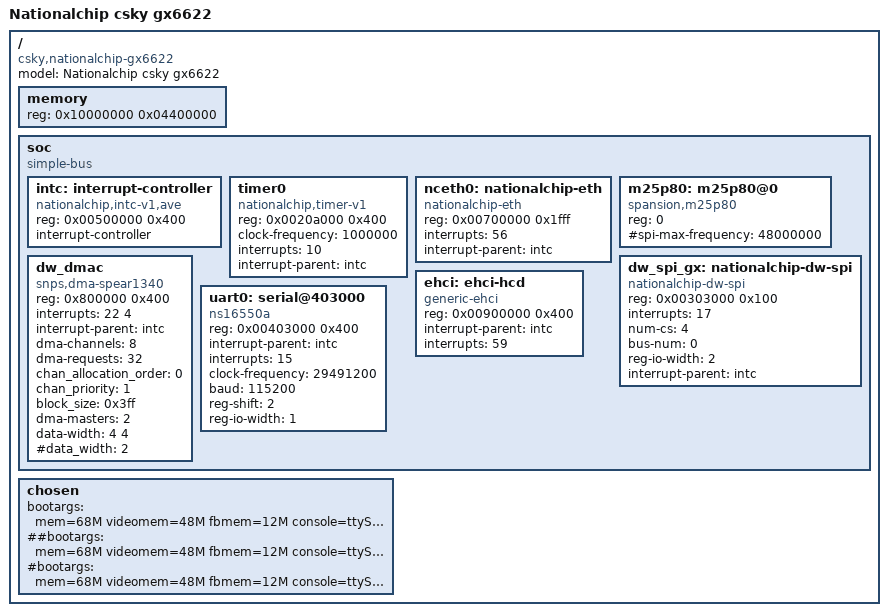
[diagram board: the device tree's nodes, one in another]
/dts-v1/;
/ {
	model = "Nationalchip csky gx6622";
	compatible = "csky,nationalchip-gx6622";
	#address-cells = <1>;
	#size-cells = <1>;

	memory {
		device_type = "memory";
		reg = <0x10000000 0x04400000>;
	};

	soc {
		#address-cells = <1>;
		#size-cells = <1>;
		compatible = "simple-bus";
		ranges;

		intc: interrupt-controller {
			compatible = "nationalchip,intc-v1,ave";
			reg = <0x00500000 0x400>;
			interrupt-controller;
			#interrupt-cells = <1>;
		};

		timer0 {
			compatible = "nationalchip,timer-v1";
			reg = <0x0020a000 0x400>;
			clock-frequency = <1000000>;
			interrupts = <10>;
			interrupt-parent = <&intc>;
		};

		nceth0: nationalchip-eth {
			compatible = "nationalchip-eth";
			reg = <0x00700000 0x1fff>;
			interrupts = <56>;
			interrupt-parent = <&intc>;
		};

		m25p80: m25p80@0 {
			compatible = "spansion,m25p80", "jedec,spi-nor";
			reg = <0>;				/* CS0 */
			#spi-max-frequency = <48000000>;
		};

		dw_spi_gx: nationalchip-dw-spi {
			compatible = "nationalchip-dw-spi";
			reg = <0x00303000 0x100>;
			interrupts = <17>;
			num-cs = <4>;
			bus-num = <0>;
			reg-io-width = <2>;
			interrupt-parent = <&intc>;
		};

		dw_dmac: dw_dmac {
			compatible = "snps,dma-spear1340";
			reg = <0x800000 0x400>;
			interrupts = <22 4>;
			interrupt-parent = <&intc>;
            
			dma-channels = <8>;
			#dma-cells = <3>;
			dma-requests = <32>;
			chan_allocation_order = <0>;
			chan_priority = <1>;
			block_size = <0x3ff>;
			dma-masters = <2>;
			data-width = <4 4>;
			#data_width = <2>;
		};

		ehci: ehci-hcd {
			compatible = "generic-ehci";
			reg = <0x00900000 0x400>;
			interrupt-parent = <&intc>;
			interrupts = <59>;
		};

		uart0: serial@403000 {
			compatible = "ns16550a";
			reg = <0x00403000 0x400>;
			interrupt-parent = <&intc>;
			interrupts = <15>;
			clock-frequency = <29491200>;
			baud = <115200>;
			reg-shift = <2>;
			reg-io-width = <1>;
		};
	};

	chosen {
		bootargs = "mem=68M videomem=48M fbmem=12M console=ttyS0,115200 init=/init root=/dev/nfs rw nfsroot=192.168.110.19:/opt/nfs2 ip=192.168.110.20";
##bootargs = "mem=68M videomem=48M fbmem=12M console=ttyS0,115200 init=/init root=/dev/nfs rw nfsroot=192.168.110.19:/opt/nfs2 ip=192.168.110.20";
		#bootargs = "mem=68M videomem=48M fbmem=12M console=ttyS0,115200 init=/linuxrc root=/dev/mtdblock3 mtdparts=m25p80:64k@0m(BOOT),64k@64k(TABLE),1536k@128k(KERNEL),2304k@1664k(ROOTFS),2880k@3968k(USER),1344k@6848k(DATA)";
	};
};
